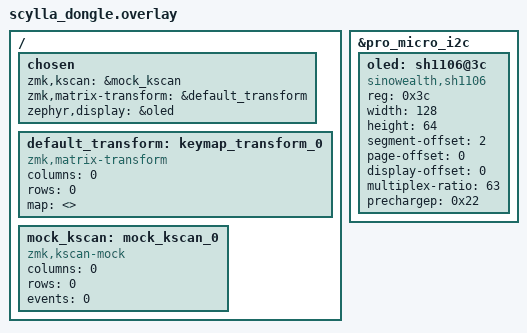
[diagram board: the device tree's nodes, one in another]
/*
 * Copyright (c) 2020 The ZMK Contributors
 * SPDX-License-Identifier: MIT
 *
 * Scylla MK2 — Dongle com display OLED SSD1306 128x64 I2C
 *
 * Ligações:
 *   VCC → 3.3V do nice!nano
 *   GND → GND
 *   SDA → pro_micro 2 (P0.17)
 *   SCL → pro_micro 3 (P0.20)
 */

#include <dt-bindings/zmk/matrix_transform.h>

/ {
    chosen {
        zmk,kscan         = &mock_kscan;
        zmk,matrix-transform = &default_transform;
        zephyr,display    = &oled;
    };

    default_transform: keymap_transform_0 {
        compatible = "zmk,matrix-transform";
        columns = <0>;
        rows = <0>;
        map = <>;
    };

    mock_kscan: mock_kscan_0 {
        compatible = "zmk,kscan-mock";
        columns = <0>;
        rows = <0>;
        events = <0>;
    };
};

/* Usa o alias pro_micro_i2c já definido no board DTS do nice!nano
 * com pinctrl configurado para SDA=P0.17 e SCL=P0.20 */
&pro_micro_i2c {
    status = "okay";

    oled: sh1106@3c {
        compatible = "sinowealth,sh1106";
        reg = <0x3c>;
        width = <128>;
        height = <64>;
        segment-offset = <2>;
        page-offset = <0>;
        display-offset = <0>;
        multiplex-ratio = <63>;
        prechargep = <0x22>;
    };
};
